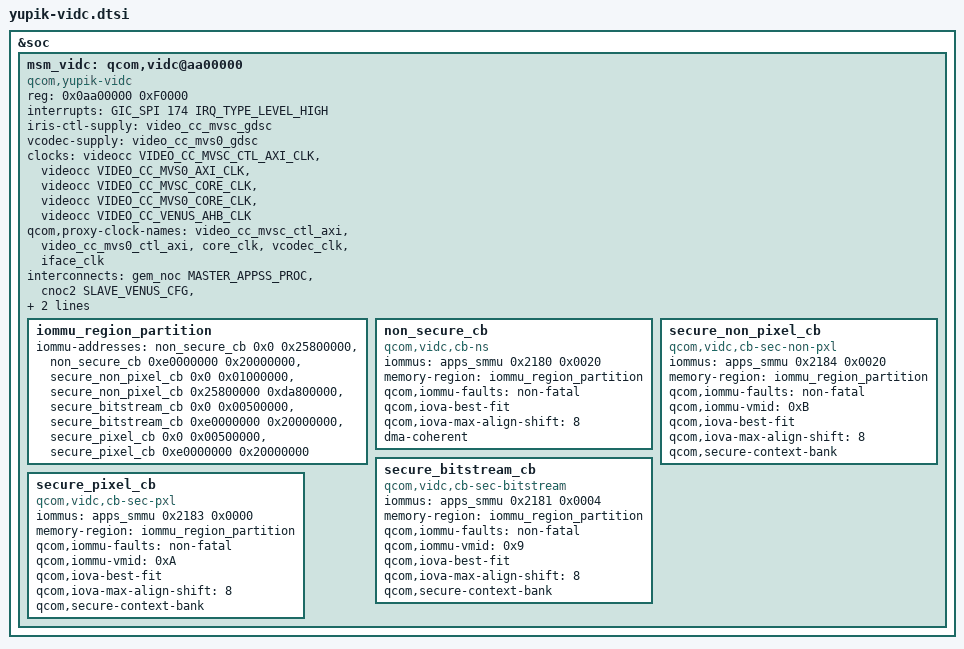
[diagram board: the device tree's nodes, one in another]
// SPDX-License-Identifier: BSD-3-Clause
/*
 * Copyright (c) Qualcomm Technologies, Inc. and/or its subsidiaries.
 */

&soc {
	msm_vidc: qcom,vidc@aa00000 {
		compatible = "qcom,yupik-vidc";
		status = "okay";
		reg = <0x0aa00000 0xF0000>;
		interrupts = <GIC_SPI 174 IRQ_TYPE_LEVEL_HIGH>;

		/* IOMMU Config */
		#address-cells = <1>;
		#size-cells = <1>;

		/* Supply */
		iris-ctl-supply = <&video_cc_mvsc_gdsc>;
		vcodec-supply = <&video_cc_mvs0_gdsc>;

		/* Clocks */
		clock-names = "video_cc_mvsc_ctl_axi",
			"video_cc_mvs0_ctl_axi", "core_clk",
			"vcodec_clk", "iface_clk";
		clocks = <&videocc VIDEO_CC_MVSC_CTL_AXI_CLK>,
			<&videocc VIDEO_CC_MVS0_AXI_CLK>,
			<&videocc VIDEO_CC_MVSC_CORE_CLK>,
			<&videocc VIDEO_CC_MVS0_CORE_CLK>,
			<&videocc VIDEO_CC_VENUS_AHB_CLK>;
		qcom,proxy-clock-names = "video_cc_mvsc_ctl_axi",
			"video_cc_mvs0_ctl_axi", "core_clk",
			"vcodec_clk", "iface_clk";

		/* Bus Interconnects */
		interconnect-names = "venus-cnoc", "venus-ddr";
		interconnects = <&gem_noc MASTER_APPSS_PROC
					&cnoc2 SLAVE_VENUS_CFG>,
				<&mmss_noc MASTER_VIDEO_P0
					&mc_virt SLAVE_EBI1>;

		/* FW load region */
		memory-region = <&video_mem>;

		/* MMUs */
		iommu_region_partition: iommu_region_partition {
			/* These IOVA regions are unique per context bank */
			iommu-addresses = <&non_secure_cb 0x0 0x25800000>,
					<&non_secure_cb 0xe0000000 0x20000000>,
				<&secure_non_pixel_cb 0x0 0x01000000>,
					<&secure_non_pixel_cb 0x25800000 0xda800000>,
				<&secure_bitstream_cb 0x0 0x00500000>,
					<&secure_bitstream_cb 0xe0000000 0x20000000>,
				<&secure_pixel_cb 0x0 0x00500000>,
					<&secure_pixel_cb 0xe0000000 0x20000000>;
		};

		non_secure_cb: non_secure_cb {
			compatible = "qcom,vidc,cb-ns";
			iommus = <&apps_smmu 0x2180 0x0020>;
			memory-region = <&iommu_region_partition>;
			qcom,iommu-faults = "non-fatal";
			qcom,iova-best-fit;
			qcom,iova-max-align-shift = <8>; /* 1 MB */
			dma-coherent;
		};

		secure_non_pixel_cb: secure_non_pixel_cb {
			compatible = "qcom,vidc,cb-sec-non-pxl";
			iommus = <&apps_smmu 0x2184 0x0020>;
			memory-region = <&iommu_region_partition>;
			qcom,iommu-faults = "non-fatal";
			qcom,iommu-vmid = <0xB>; /* VMID_CP_NON_PIXEL */
			qcom,iova-best-fit;
			qcom,iova-max-align-shift = <8>; /* 1 MB */
			qcom,secure-context-bank;
		};

		secure_bitstream_cb: secure_bitstream_cb {
			compatible = "qcom,vidc,cb-sec-bitstream";
			iommus = <&apps_smmu 0x2181 0x0004>;
			memory-region = <&iommu_region_partition>;
			qcom,iommu-faults = "non-fatal";
			qcom,iommu-vmid = <0x9>; /* VMID_CP_BITSTREAM */
			qcom,iova-best-fit;
			qcom,iova-max-align-shift = <8>; /* 1 MB */
			qcom,secure-context-bank;
		};

		secure_pixel_cb: secure_pixel_cb {
			compatible = "qcom,vidc,cb-sec-pxl";
			iommus = <&apps_smmu 0x2183 0x0000>;
			memory-region = <&iommu_region_partition>;
			qcom,iommu-faults = "non-fatal";
			qcom,iommu-vmid = <0xA>; /* VMID_CP_PIXEL */
			qcom,iova-best-fit;
			qcom,iova-max-align-shift = <8>; /* 1 MB */
			qcom,secure-context-bank;
		};
	};
};
